# ATxmega128A1 register map
Vendor: Atmel; File version: 1.0
CPU: other r0p0, little endian, no MPU, no FPU, 4 interrupt priority bits
Registers are 8-bit, read-write, reset 0x0 unless marked. A register's access mark holds for its fields unless they carry their own. Offsets are from the block's base; [hi:lo] are bit positions; {n}, {i} and the like mark numbered series.

## AES — AES Module
Base 0x000000C0
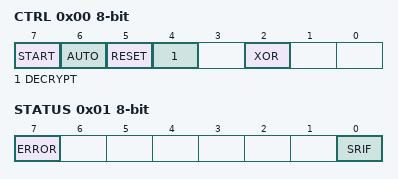
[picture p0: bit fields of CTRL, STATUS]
0x00 CTRL — AES Control Register
  [7] START — Start/Run
  [6] AUTO — Auto Start Trigger
  [5] RESET — AES Software Reset
  [4] DECRYPT — Decryption / Direction
  [2] XOR — State XOR Load Enable
0x01 STATUS — AES Status Register
  [7] ERROR — AES Error
  [0] SRIF — State Ready Interrupt Flag
0x02 STATE — AES State Register
0x03 KEY — AES Key Register
0x04 INTCTRL — AES Interrupt Control Register
  [1:0] INTLVL — Interrupt level
    0=OFF (Interrupt Disabled); 1=LO (Low Level); 2=MED (Medium Level); 3=HI (High Level)

## AWEXC — 16-bit Timer/Counter With PWM
Base 0x00000880
Same registers: AWEXE 0x00000A80
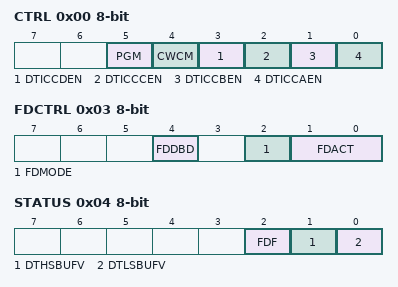
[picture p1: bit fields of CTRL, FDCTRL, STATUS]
0x00 CTRL — Control Register
  [5] PGM — Pattern Generation Mode
  [4] CWCM — Common Waveform Channel Mode
  [3] DTICCDEN — Dead Time Insertion Compare Channel D Enable
  [2] DTICCCEN — Dead Time Insertion Compare Channel C Enable
  [1] DTICCBEN — Dead Time Insertion Compare Channel B Enable
  [0] DTICCAEN — Dead Time Insertion Compare Channel A Enable
0x02 FDEMASK — Fault Detection Event Mask
0x03 FDCTRL — Fault Detection Control Register
  [4] FDDBD — Fault Detect on Disable Break Disable
  [2] FDMODE — Fault Detect Mode
  [1:0] FDACT — Fault Detect Action
    0=NONE (No Fault Protection); 1=CLEAROE (Clear Output Enable Bits); 3=CLEARDIR (Clear I/O Port Direction Bits)
0x04 STATUS
  [2] FDF — Fault Detect Flag
  [1] DTHSBUFV — Dead Time High Side Buffer Valid
  [0] DTLSBUFV — Dead Time Low Side Buffer Valid
0x06 DTBOTH — Dead Time Both Sides
0x07 DTBOTHBUF — Dead Time Both Sides Buffer
0x08 DTLS — Dead Time Low Side
0x09 DTHS — Dead Time High Side
0x0A DTLSBUF — Dead Time Low Side Buffer
0x0B DTHSBUF — Dead Time High Side Buffer
0x0C OUTOVEN — Output Override Enable

## CLK — Clock System
Base 0x00000040
0x00 CTRL — Control Register
  [2:0] SCLKSEL — System Clock Selection
    0=RC2M (Internal 2MHz RC Oscillator); 1=RC32M (Internal 32MHz RC Oscillator); 2=RC32K (Internal 32kHz RC Oscillator); 3=XOSC (External Crystal Oscillator or Clock); 4=PLL (Phase Locked Loop)
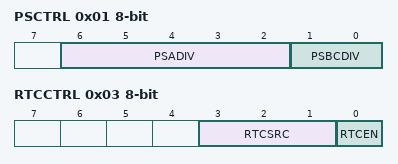
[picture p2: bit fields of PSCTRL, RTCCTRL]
0x01 PSCTRL — Prescaler Control Register
  [6:2] PSADIV — Prescaler A Division Factor
    0=Divide by 1; 1=Divide by 2; 3=Divide by 4; 5=Divide by 8; 7=Divide by 16; 9=Divide by 32; 11=Divide by 64; 13=Divide by 128; 15=Divide by 256; 17=Divide by 512
  [1:0] PSBCDIV — Prescaler B and C Division factor
    0=Divide B by 1 and C by 1; 1=1_2 (Divide B by 1 and C by 2); 2=4_1 (Divide B by 4 and C by 1); 3=2_2 (Divide B by 2 and C by 2)
0x02 LOCK
  [0] LOCK — Clock System Lock
0x03 RTCCTRL — RTC Control Register
  [3:1] RTCSRC — RTC Clock Source
    0=ULP (1kHz from internal 32kHz ULP); 1=TOSC (1kHz from 32kHz crystal oscillator on TOSC); 2=RCOSC (1kHz from internal 32kHz RC oscillator); 5=TOSC32 (32kHz from 32kHz crystal oscillator on TOSC)
  [0] RTCEN — RTC Clock Source Enable

## CPU
Base 0x00000030
0x04 CCP — Configuration Change Protection
  [7:0] CCP — CCP signature
    157=SPM (SPM Instruction Protection); 216=IOREG (IO Register Protection)
0x08 RAMPD
0x09 RAMPX
0x0A RAMPY
0x0B RAMPZ
0x0C EIND — Extended Indirect Jump
0x0D SPL — Stack Pointer Low
0x0E SPH — Stack Pointer High

## DACA — Digital/Analog Converter
Base 0x00000300
Same registers: DACB 0x00000320
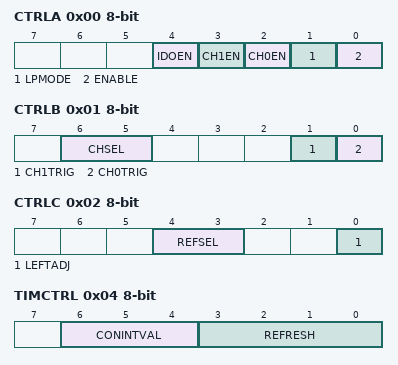
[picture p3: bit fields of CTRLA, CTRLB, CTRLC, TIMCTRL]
0x00 CTRLA — Control Register A
  [4] IDOEN — Internal Output Enable
  [3] CH1EN — Channel 1 Output Enable
  [2] CH0EN — Channel 0 Output Enable
  [1] LPMODE — Low Power Mode
  [0] ENABLE
0x01 CTRLB — Control Register B
  [6:5] CHSEL — Channel Select
    0=SINGLE (Single channel operation (Channel A only)); 2=DUAL (Dual channel operation (S/H on both channels))
  [1] CH1TRIG — Channel 1 Event Trig Enable
  [0] CH0TRIG — Channel 0 Event Trig Enable
0x02 CTRLC — Control Register C
  [4:3] REFSEL — Reference Select
    0=INT1V (Internal 1V); 1=AVCC (Analog supply voltage); 2=AREFA (External reference on AREF on PORTA); 3=AREFB (External reference on AREF on PORTB)
  [0] LEFTADJ — Left-adjust Result
0x03 EVCTRL — Event Input Control
  [2:0] EVSEL — Event Input Selection
    {v}=Event Channel {v} (v=0..7)
0x04 TIMCTRL — Timing Control
  [6:4] CONINTVAL — Conversion Intercal
    0=1CLK (1 CLK / 2 CLK in S/H mode); 1=2CLK (2 CLK / 3 CLK in S/H mode); 2=4CLK (4 CLK / 6 CLK in S/H mode); 3=8CLK (8 CLK / 12 CLK in S/H mode); 4=16CLK (16 CLK / 24 CLK in S/H mode); 5=32CLK (32 CLK / 48 CLK in S/H mode); 6=64CLK (64 CLK / 96 CLK in S/H mode); 7=128CLK (128 CLK / 192 CLK in S/H mode)
  [3:0] REFRESH — Refresh Timing Control
    0=16CLK; 1=32CLK; 2=64CLK; 3=128CLK; 4=256CLK; 5=512CLK; 6=1024CLK; 7=2048CLK; 8=4096CLK; 9=8192CLK; 10=16384CLK; 11=32768CLK; 12=65536CLK; 15=OFF (Auto refresh OFF)
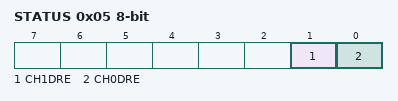
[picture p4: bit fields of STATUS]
0x05 STATUS
  [1] CH1DRE — Channel 1 Data Register Empty
  [0] CH0DRE — Channel 0 Data Register Empty
0x08 GAINCAL — Gain Calibration
  [6:0] GAINCAL
0x09 OFFSETCAL — Offset Calibration
  [6:0] OFFSETCAL
0x18 CH0DATA 16-bit (reset mask 0xFF) — Channel 0 Data
0x1A CH1DATA 16-bit (reset mask 0xFF) — Channel 1 Data
